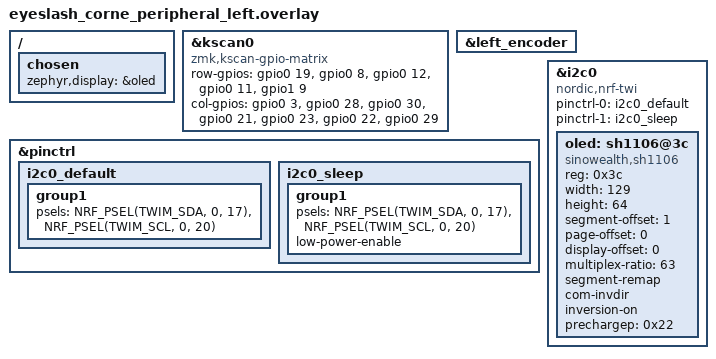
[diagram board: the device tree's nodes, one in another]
/*
*
* Copyright (c) 2021 Darryl deHaan
* SPDX-License-Identifier: MIT
*
*/

#include "eyeslash_corne.dtsi"

/ {
    chosen {
        zephyr,display = &oled;
    };
};

&kscan0 {
    compatible = "zmk,kscan-gpio-matrix";
    row-gpios
        = <&gpio0 19 (GPIO_ACTIVE_HIGH | GPIO_PULL_DOWN)>
        , <&gpio0 8 (GPIO_ACTIVE_HIGH | GPIO_PULL_DOWN)>
        , <&gpio0 12 (GPIO_ACTIVE_HIGH | GPIO_PULL_DOWN)>
        , <&gpio0 11 (GPIO_ACTIVE_HIGH | GPIO_PULL_DOWN)>
        , <&gpio1 9 (GPIO_ACTIVE_HIGH | GPIO_PULL_DOWN)>
        ;
    col-gpios
        = <&gpio0 3 GPIO_ACTIVE_HIGH>
        , <&gpio0 28 GPIO_ACTIVE_HIGH>
        , <&gpio0 30 GPIO_ACTIVE_HIGH>
        , <&gpio0 21 GPIO_ACTIVE_HIGH>
        , <&gpio0 23 GPIO_ACTIVE_HIGH>
        , <&gpio0 22 GPIO_ACTIVE_HIGH>
        , <&gpio0 29 GPIO_ACTIVE_HIGH>
        ;
};

&left_encoder {
    status = "okay";
};

&pinctrl {
    i2c0_default: i2c0_default {
        group1 {
            psels = <NRF_PSEL(TWIM_SDA, 0, 17)>,
                <NRF_PSEL(TWIM_SCL, 0, 20)>;
        };
    };

    i2c0_sleep: i2c0_sleep {
        group1 {
            psels = <NRF_PSEL(TWIM_SDA, 0, 17)>,
                <NRF_PSEL(TWIM_SCL, 0, 20)>;
            low-power-enable;
        };
    };
};

&i2c0 {
    status = "okay";
    compatible = "nordic,nrf-twi";
    pinctrl-0 = <&i2c0_default>;
    pinctrl-1 = <&i2c0_sleep>;
    oled: sh1106@3c {
        compatible = "sinowealth,sh1106";
        reg = <0x3c>;
        width = <129>;
        height = <64>;
        segment-offset = <1>;
        page-offset = <0>;
        display-offset = <0>;
        multiplex-ratio = <63>;
        segment-remap;
        com-invdir;
        inversion-on;
        prechargep = <0x22>;
    };
};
